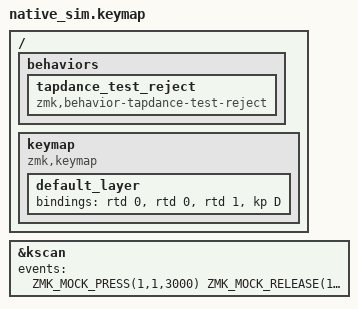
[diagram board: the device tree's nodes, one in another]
#include <dt-bindings/zmk/keys.h>
#include <behaviors.dtsi>
#include <behaviors/runtime_tapdance.dtsi>
#include <dt-bindings/zmk/kscan_mock.h>
/ {
    behaviors {
        tapdance_test_reject: tapdance_test_reject {
            compatible = "zmk,behavior-tapdance-test-reject";
            #binding-cells = <0>;
        };
    };
    keymap {
        compatible = "zmk,keymap";
        default_layer { bindings = <&rtd 0 &rtd 0 &rtd 1 &kp D>; };
    };
};
&kscan { events = <ZMK_MOCK_PRESS(1,1,3000) ZMK_MOCK_RELEASE(1,1,10)>; };
